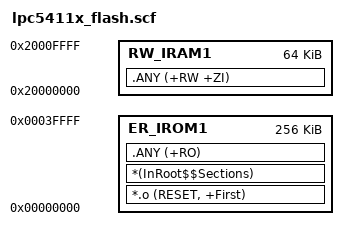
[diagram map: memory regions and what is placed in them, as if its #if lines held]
#! armcc -E

; ROM
; | 0x00000000 |
; --------------
; |   vector   |
; --------------
; |     RO     |
; | 0x00040000 |

; RAM
; | 0x20000000 |
; --------------
; |    data    |
; --------------
; |    Heap    |
; --------------
; |   Stack    |
; --------------
; | 0x00010000 |

; vector region
#define Vector_Start                  0x00000000
#define Vector_Size                   0x00000100
; code region
#define ROM_Start                     0x00000100
#define ROM_Size                      0x00040000
; data region
#define RAM_Start                     0x20000000
#define RAM_Size                      0x00010000
; heap region
; stack reion

#if (defined(__stack_size__))
  #define Stack_Size                   __stack_size__
#else
  #define Stack_Size                   0x0400
#endif

#if (defined(__heap_size__))
  #define Heap_Size                    __heap_size__
#else
  #define Heap_Size                    0x0400
#endif

#define RTT_HEAP_LENGTH		(RAM_Start - ImageLength(RW_m_data) - ImageLength(HEAP_Region) - ImageLength(STACK_Region))
    
;LR_IROM1 0x00000000 0x00040000  {    ; load region size_region
;  VECTOR_ROM Vector_Start Vector_Size { ; load address = execution address
;    *.o (RESET, +First)
;  }
;  ER_IROM1 ROM_Start+Vector_Size ROM_Size-Vector_Size  {  
;   *(InRoot$$Sections)
;   .ANY (+RO)
;  }
;  RW_IRAM1 RAM_Start RAM_Size-Heap_Size-Stack_Size {  ; RW data
;   .ANY (+RW +ZI)
;  }
;  HEAP_Region ((ImageLimit(RW_m_data) == RAM_Size) ? ImageLimit(RW_m_data) : +0) EMPTY Heap_Size { ; Heap region growing up
;  }
;  STACK_Region RAM_Start+RAM_Size EMPTY -Stack_Size { ; Stack region growing down
;  }
;  RTT_HEAP +0 EMPTY RTT_HEAP_LENGTH {
;  }  
;}

LR_IROM1 0x00000000 0x00040000  {    ; load region size_region
  ER_IROM1 0x00000000 0x00040000 {  
   *.o (RESET, +First)
   *(InRoot$$Sections)
   .ANY (+RO)
  }
  RW_IRAM1 0x20000000 0x00010000{  ; RW data
   .ANY (+RW +ZI)
  }
}


